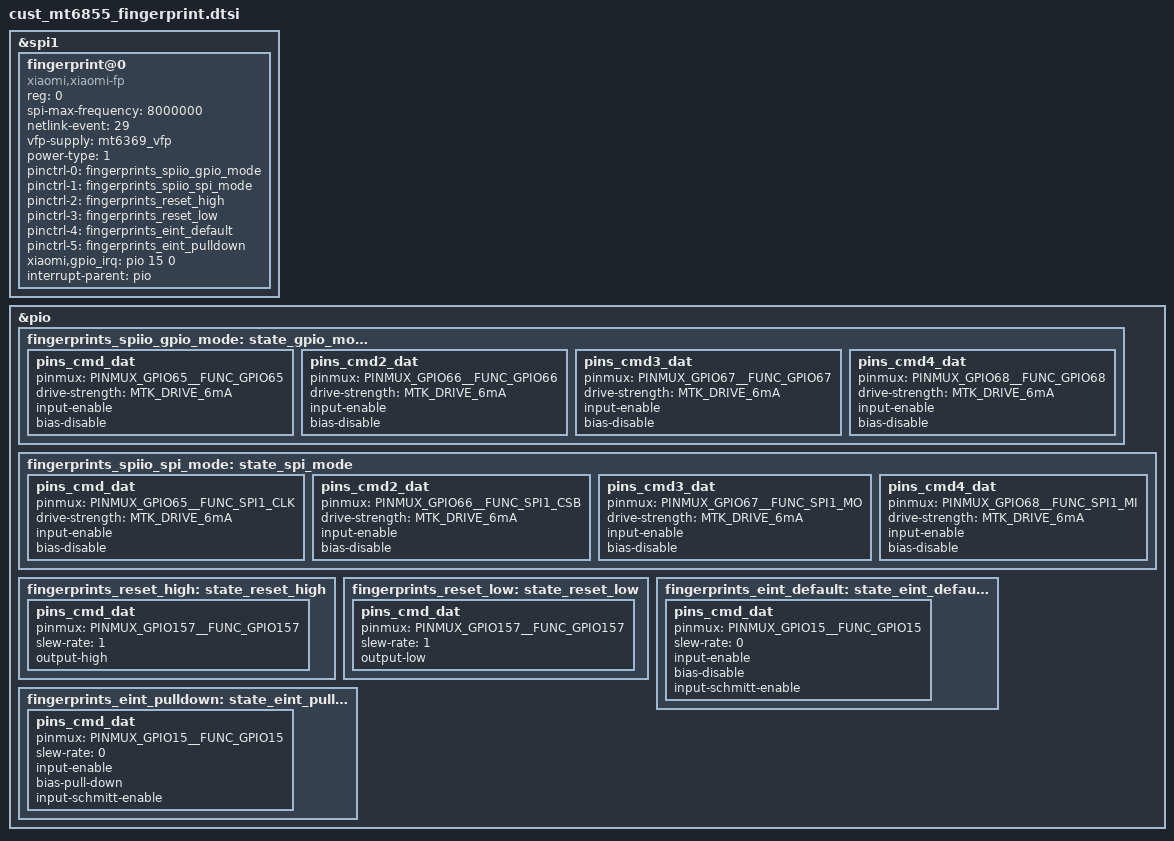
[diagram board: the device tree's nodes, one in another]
/* fingerprint start */
&spi1 {
	#address-cells = <1>;
	#size-cells = <0>;
	fingerprint@0 {
		compatible = "xiaomi,xiaomi-fp";
		reg = <0>;
		spi-max-frequency = <8000000>;
		netlink-event = <29>;
		vfp-supply = <&mt6369_vfp>;
		power-type = <1>;
		pinctrl-names = "spiio_gpio_mode", "spiio_spi_mode", "reset_high", "reset_low", "eint_default", "eint_pulldown";
		pinctrl-0 = <&fingerprints_spiio_gpio_mode>;
		pinctrl-1 = <&fingerprints_spiio_spi_mode>;
		pinctrl-2 = <&fingerprints_reset_high>;
		pinctrl-3 = <&fingerprints_reset_low>;
		pinctrl-4 = <&fingerprints_eint_default>;
		pinctrl-5 = <&fingerprints_eint_pulldown>;
		xiaomi,gpio_irq = <&pio 15 0>;
		interrupt-parent = <&pio>;
		status = "okay";
	};
};

&pio {
	fingerprints_spiio_gpio_mode: state_gpio_mode {
		pins_cmd_dat {
			pinmux = <PINMUX_GPIO65__FUNC_GPIO65>;
			drive-strength = <MTK_DRIVE_6mA>;
			input-enable;
			bias-disable;
		};
		pins_cmd2_dat {
			pinmux = <PINMUX_GPIO66__FUNC_GPIO66>;
			drive-strength = <MTK_DRIVE_6mA>;
			input-enable;
			bias-disable;
		};
		pins_cmd3_dat {
			pinmux = <PINMUX_GPIO67__FUNC_GPIO67>;
			drive-strength = <MTK_DRIVE_6mA>;
			input-enable;
			bias-disable;
		};
		pins_cmd4_dat {
			pinmux = <PINMUX_GPIO68__FUNC_GPIO68>;
			drive-strength = <MTK_DRIVE_6mA>;
			input-enable;
			bias-disable;
		};
	};
	fingerprints_spiio_spi_mode: state_spi_mode {
		pins_cmd_dat {
			pinmux = <PINMUX_GPIO65__FUNC_SPI1_CLK>;
			drive-strength = <MTK_DRIVE_6mA>;
			input-enable;
			bias-disable;
		};
		pins_cmd2_dat {
			pinmux = <PINMUX_GPIO66__FUNC_SPI1_CSB>;
			drive-strength = <MTK_DRIVE_6mA>;
			input-enable;
			bias-disable;
		};
		pins_cmd3_dat {
			pinmux = <PINMUX_GPIO67__FUNC_SPI1_MO>;
			drive-strength = <MTK_DRIVE_6mA>;
			input-enable;
			bias-disable;
		};
		pins_cmd4_dat {
			pinmux = <PINMUX_GPIO68__FUNC_SPI1_MI>;
			drive-strength = <MTK_DRIVE_6mA>;
			input-enable;
			bias-disable;
		};
	};
	fingerprints_reset_high: state_reset_high {
		pins_cmd_dat {
			pinmux = <PINMUX_GPIO157__FUNC_GPIO157>;
			slew-rate = <1>;
			output-high;
		};
	};
	fingerprints_reset_low: state_reset_low {
		pins_cmd_dat {
			pinmux = <PINMUX_GPIO157__FUNC_GPIO157>;
			slew-rate = <1>;
			output-low;
		};
	};
	fingerprints_eint_default: state_eint_default {
		pins_cmd_dat {
			pinmux = <PINMUX_GPIO15__FUNC_GPIO15>;
			slew-rate = <0>;
			input-enable;
			bias-disable;
			input-schmitt-enable;
		};
	};
	fingerprints_eint_pulldown: state_eint_pulldown {
		pins_cmd_dat {
			pinmux = <PINMUX_GPIO15__FUNC_GPIO15>;
			slew-rate = <0>;
			input-enable;
			bias-pull-down;
			input-schmitt-enable;
		};
	};
};
/* fingerprint end */
